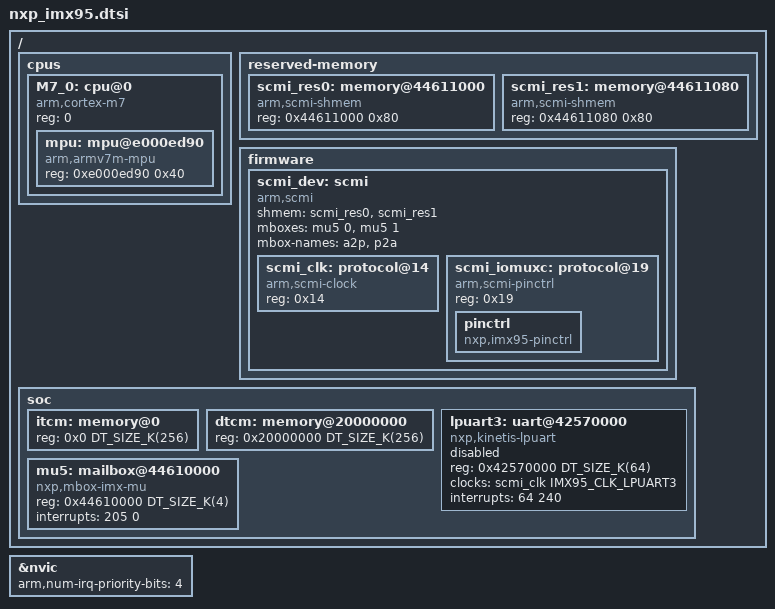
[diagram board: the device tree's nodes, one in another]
/*
 * Copyright 2024 NXP
 *
 * SPDX-License-Identifier: Apache-2.0
 */

#include <arm/armv7-m.dtsi>
#include <mem.h>
#include <zephyr/dt-bindings/clock/imx95-clock.h>

/ {
	cpus {
		#address-cells = <1>;
		#size-cells = <0>;

		M7_0: cpu@0 {
			device_type = "cpu";
			compatible = "arm,cortex-m7";
			reg = <0>;

			#address-cells = <1>;
			#size-cells = <1>;

			mpu: mpu@e000ed90 {
				compatible = "arm,armv7m-mpu";
				/* TODO: size needs double checking */
				reg = <0xe000ed90 0x40>;
			};
		};
	};

	reserved-memory {
		#address-cells = <1>;
		#size-cells = <1>;

		scmi_res0: memory@44611000 {
			compatible = "arm,scmi-shmem";
			reg = <0x44611000 0x80>;
		};

		scmi_res1: memory@44611080 {
			compatible = "arm,scmi-shmem";
			reg = <0x44611080 0x80>;
		};
	};

	firmware {
		scmi_dev: scmi {
			compatible = "arm,scmi";
			shmem = <&scmi_res0>, <&scmi_res1>;
			mboxes = <&mu5 0>, <&mu5 1>;
			mbox-names = "a2p", "p2a";

			#address-cells = <1>;
			#size-cells = <0>;

			scmi_clk: protocol@14 {
				compatible = "arm,scmi-clock";
				reg = <0x14>;
				#clock-cells = <1>;
			};

			scmi_iomuxc: protocol@19 {
				compatible = "arm,scmi-pinctrl";
				reg = <0x19>;

				pinctrl: pinctrl {
					compatible = "nxp,imx95-pinctrl";
				};
			};
		};
	};

	soc {
		itcm: memory@0 {
			/* TODO: is there a need to add compatible here? */
			reg = <0x0 DT_SIZE_K(256)>;
		};

		dtcm: memory@20000000 {
			/* TODO: is there a need to add compatible here? */
			reg = <0x20000000 DT_SIZE_K(256)>;
		};

		lpuart3: uart@42570000 {
			compatible = "nxp,kinetis-lpuart";
			reg = <0x42570000 DT_SIZE_K(64)>;
			clocks = <&scmi_clk IMX95_CLK_LPUART3>;
			interrupts = <64 240>;
			status = "disabled";
		};

		mu5: mailbox@44610000 {
			compatible = "nxp,mbox-imx-mu";
			reg = <0x44610000 DT_SIZE_K(4)>;
			interrupts = <205 0>;
			#mbox-cells = <1>;
		};
	};
};

&nvic {
	arm,num-irq-priority-bits = <4>;
};
